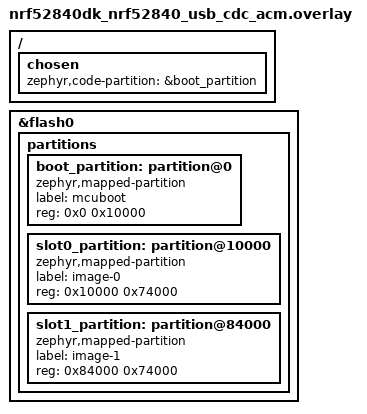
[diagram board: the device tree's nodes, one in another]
/delete-node/ &boot_partition;
/delete-node/ &slot0_partition;
/delete-node/ &slot1_partition;

/ {
	chosen {
		zephyr,code-partition = &boot_partition;
	};
};

&flash0 {
	partitions {
		boot_partition: partition@0 {
			compatible = "zephyr,mapped-partition";
			label = "mcuboot";
			reg = <0x0 0x10000>;
		};

		slot0_partition: partition@10000 {
			compatible = "zephyr,mapped-partition";
			label = "image-0";
			reg = <0x10000 0x74000>;
		};

		slot1_partition: partition@84000 {
			compatible = "zephyr,mapped-partition";
			label = "image-1";
			reg = <0x84000 0x74000>;
		};
	};
};
